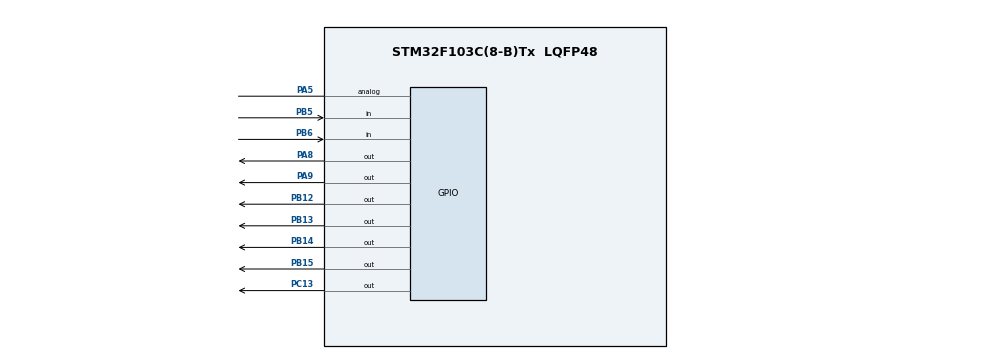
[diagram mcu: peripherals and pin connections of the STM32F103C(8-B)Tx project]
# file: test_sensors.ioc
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Mcu.Family=STM32F1
Mcu.Name=STM32F103C(8-B)Tx
Mcu.Package=LQFP48
NVIC.PriorityGroup=NVIC_PRIORITYGROUP_4
PA5.Signal=GPIO_Analog
PA8.Signal=GPIO_Output
PA9.Signal=GPIO_Output
PB12.Signal=GPIO_Output
PB13.Signal=GPIO_Output
PB14.Signal=GPIO_Output
PB15.Signal=GPIO_Output
PB5.GPIO_PuPd=GPIO_PULLUP
PB5.Signal=GPIO_Input
PB6.GPIO_PuPd=GPIO_PULLUP
PB6.Signal=GPIO_Input
PC13-TAMPER-RTC.Signal=GPIO_Output
ProjectManager.HeapSize=0x200
ProjectManager.StackSize=0x400
ProjectManager.TargetToolchain=Makefile
RCC.APB1Freq_Value=8000000
RCC.APB2Freq_Value=8000000
VP_SYS_VS_ND.Mode=No_Debug
board=custom

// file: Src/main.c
/* USER CODE BEGIN Header */
/**
  ******************************************************************************
  * @file           : main.c
  * @brief          : Main program body
  ******************************************************************************
  * @attention
  *
  * <h2><center>&copy; Copyright (c) 2019 STMicroelectronics.
  * All rights reserved.</center></h2>
  *
  * This software component is licensed by ST under BSD 3-Clause license,
  * the "License"; You may not use this file except in compliance with the
  * License. You may obtain a copy of the License at:
  *                        opensource.org/licenses/BSD-3-Clause
  *
  ******************************************************************************
  */
/* USER CODE END Header */

#include "main.h"

void SystemClock_Config(void);
static void MX_GPIO_Init(void);

int main(void)
{

  /* MCU Configuration--------------------------------------------------------*/

  /* Reset of all peripherals, Initializes the Flash interface and the Systick. */
  HAL_Init();

  /* Configure the system clock */
  SystemClock_Config();

  /* Initialize all configured peripherals */
  MX_GPIO_Init();
  /* USER CODE BEGIN 2 */

  Lcd_PortType ports[] = {GPIOB, GPIOB, GPIOB, GPIOB};

  Lcd_PinType pins[] = {GPIO_PIN_12, GPIO_PIN_13, GPIO_PIN_14, GPIO_PIN_15};
  Lcd_HandleTypeDef lcd;

  lcd = Lcd_create(ports, pins, GPIOA, GPIO_PIN_8, GPIOA, GPIO_PIN_9, LCD_4_BIT_MODE);

  Lcd_cursor(&lcd, 1, 0);
  Lcd_string(&lcd, "Hello there, Brandon and James");
  HAL_Delay(2500);
  Lcd_clear(&lcd);
  Lcd_cursor(&lcd, 0, 0);
  Lcd_string(&lcd, "Encoder1: ");
  Lcd_cursor(&lcd, 1, 0);
  Lcd_string(&lcd, "Encoder2: ");
  Lcd_cursor(&lcd, 2, 0);
  Lcd_string(&lcd, "ForceSen: ");
  /* USER CODE END 2 */

  /* Infinite loop */
  while (1) {

      if(HAL_GPIO_ReadPin(GPIOB, GPIO_PIN_5) == 1) {
      Lcd_cursor(&lcd, 0, 9);
      Lcd_int(&lcd, 1);
    } else {
      Lcd_cursor(&lcd, 0, 9);
      Lcd_int(&lcd, 0);
    }

    if(HAL_GPIO_ReadPin(GPIOB, GPIO_PIN_6) == 1) {
      Lcd_cursor(&lcd, 1, 9);
      Lcd_int(&lcd, 1);
    } else {
      Lcd_cursor(&lcd, 1, 9);
      Lcd_int(&lcd, 0);
    }

    /* USER CODE BEGIN 3 */
    // HAL_Delay(50);
  }
  /* USER CODE END 3 */
}

void SystemClock_Config(void)
{
  RCC_OscInitTypeDef RCC_OscInitStruct = {0};
  RCC_ClkInitTypeDef RCC_ClkInitStruct = {0};

  /** Initializes the CPU, AHB and APB busses clocks
  */
  RCC_OscInitStruct.OscillatorType = RCC_OSCILLATORTYPE_HSI;
  RCC_OscInitStruct.HSIState = RCC_HSI_ON;
  RCC_OscInitStruct.HSICalibrationValue = RCC_HSICALIBRATION_DEFAULT;
  RCC_OscInitStruct.PLL.PLLState = RCC_PLL_NONE;
  if (HAL_RCC_OscConfig(&RCC_OscInitStruct) != HAL_OK)
  {
    Error_Handler();
  }
  /** Initializes the CPU, AHB and APB busses clocks
  */
  RCC_ClkInitStruct.ClockType = RCC_CLOCKTYPE_HCLK|RCC_CLOCKTYPE_SYSCLK
                              |RCC_CLOCKTYPE_PCLK1|RCC_CLOCKTYPE_PCLK2;
  RCC_ClkInitStruct.SYSCLKSource = RCC_SYSCLKSOURCE_HSI;
  RCC_ClkInitStruct.AHBCLKDivider = RCC_SYSCLK_DIV1;
  RCC_ClkInitStruct.APB1CLKDivider = RCC_HCLK_DIV1;
  RCC_ClkInitStruct.APB2CLKDivider = RCC_HCLK_DIV1;

  if (HAL_RCC_ClockConfig(&RCC_ClkInitStruct, FLASH_LATENCY_0) != HAL_OK)
  {
    Error_Handler();
  }
}

static void MX_GPIO_Init(void)
{
  GPIO_InitTypeDef GPIO_InitStruct = {0};

  /* GPIO Ports Clock Enable */
  __HAL_RCC_GPIOC_CLK_ENABLE();
  __HAL_RCC_GPIOA_CLK_ENABLE();
  __HAL_RCC_GPIOB_CLK_ENABLE();

  /*Configure GPIO pin Output Level */
  HAL_GPIO_WritePin(GPIOC, GPIO_PIN_13, GPIO_PIN_RESET);

  /*Configure GPIO pin Output Level */
  HAL_GPIO_WritePin(GPIOB, GPIO_PIN_12|GPIO_PIN_13|GPIO_PIN_14|GPIO_PIN_15, GPIO_PIN_RESET);

  /*Configure GPIO pin Output Level */
  HAL_GPIO_WritePin(GPIOA, GPIO_PIN_8|GPIO_PIN_9, GPIO_PIN_RESET);

  /*Configure GPIO pin : PC13 */
  GPIO_InitStruct.Pin = GPIO_PIN_13;
  GPIO_InitStruct.Mode = GPIO_MODE_OUTPUT_PP;
  GPIO_InitStruct.Pull = GPIO_NOPULL;
  GPIO_InitStruct.Speed = GPIO_SPEED_FREQ_LOW;
  HAL_GPIO_Init(GPIOC, &GPIO_InitStruct);

  /*Configure GPIO pin : PA5 */
  GPIO_InitStruct.Pin = GPIO_PIN_5;
  GPIO_InitStruct.Mode = GPIO_MODE_ANALOG;
  HAL_GPIO_Init(GPIOA, &GPIO_InitStruct);

  /*Configure GPIO pins : PB12 PB13 PB14 PB15 */
  GPIO_InitStruct.Pin = GPIO_PIN_12|GPIO_PIN_13|GPIO_PIN_14|GPIO_PIN_15;
  GPIO_InitStruct.Mode = GPIO_MODE_OUTPUT_PP;
  GPIO_InitStruct.Pull = GPIO_NOPULL;
  GPIO_InitStruct.Speed = GPIO_SPEED_FREQ_LOW;
  HAL_GPIO_Init(GPIOB, &GPIO_InitStruct);

  /*Configure GPIO pins : PA8 PA9 */
  GPIO_InitStruct.Pin = GPIO_PIN_8|GPIO_PIN_9;
  GPIO_InitStruct.Mode = GPIO_MODE_OUTPUT_PP;
  GPIO_InitStruct.Pull = GPIO_NOPULL;
  GPIO_InitStruct.Speed = GPIO_SPEED_FREQ_LOW;
  HAL_GPIO_Init(GPIOA, &GPIO_InitStruct);

  /*Configure GPIO pins : PB5 PB6 */
  GPIO_InitStruct.Pin = GPIO_PIN_5|GPIO_PIN_6;
  GPIO_InitStruct.Mode = GPIO_MODE_INPUT;
  GPIO_InitStruct.Pull = GPIO_PULLUP;
  HAL_GPIO_Init(GPIOB, &GPIO_InitStruct);

}

void Error_Handler(void)
{
}

/************************ (C) COPYRIGHT STMicroelectronics *****END OF FILE****/
